# SF32LB58x register map
File version: 1.0
CPU: CM33 r0p1, little endian, MPU, FPU, 3 interrupt priority bits
Registers are 32-bit, read-write, reset 0x0 unless marked. A register's access mark holds for its fields unless they carry their own. Offsets are from the block's base; [hi:lo] are bit positions.

## WDT1
Base 0x40014000
Same registers: WDT2 0x5000B000, IWDT 0x5004C000
0x00 WDT_CVR0 — WatchDog Counter Value 0
  [23:0] COUNT_VALUE_0 — Count Value for 1st TimeOut
0x04 WDT_CVR1 — WatchDog Counter Value 1
  [23:0] COUNT_VALUE_1 — Count Value for 2nd TimeOut
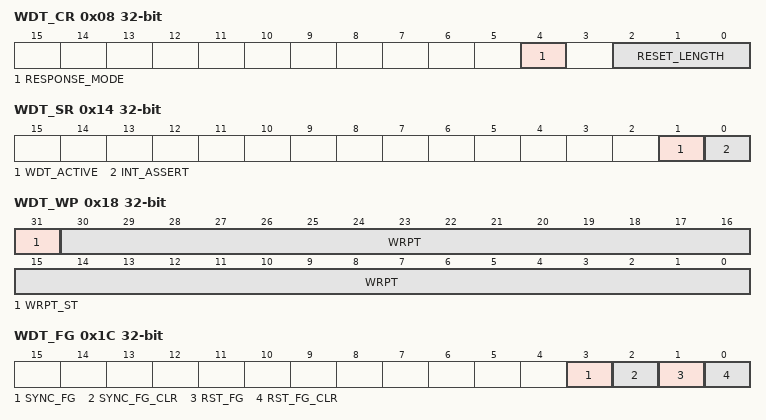
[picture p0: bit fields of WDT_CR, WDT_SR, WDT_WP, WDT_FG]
0x08 WDT_CR — WatchDog Control Register
  [4] RESPONSE_MODE — 0:reset only, 1:interrupt and reset
  [2:0] RESET_LENGTH — reset pulse length in number of wdt clock cycles
0x0C WDT_CCR — WatchDog Counter Control Register
  [7:0] COUNTER_CONTROL — SinglePulse /Write 8'h76 to restart, write8'h34 to stop, else do nothing
0x10 WDT_ICR — WatchDog Interrupt Clear Register
  [0] INT_CLR — SinglePulse /A pulse to clear interrupt
0x14 WDT_SR — WatchDog Status Register
  [1] WDT_ACTIVE — Watchdog runs when 1, else 0
  [0] INT_ASSERT — Interrupt assert when 1
0x18 WDT_WP — WatchDog Write Protect Register
  [31] WRPT_ST — 1 indicates write protect is active
  [30:0] WRPT — write 0x58ab99fc generate write_protect, write 0x51ff8621 to release
0x1C WDT_FG — WatchDog Flag Register
  [3] SYNC_FG — 1 indicates one transition from system clk to wdt clk has complicated
  [2] SYNC_FG_CLR — SinglePulse/A pulse to clear sync flag
  [1] RST_FG — 1 indicates wdt has already reset system
  [0] RST_FG_CLR — SinglePulse/A pulse to clear reset flag

## PDM1
Base 0x4001A000
Same registers: PDM2 0x4001B000
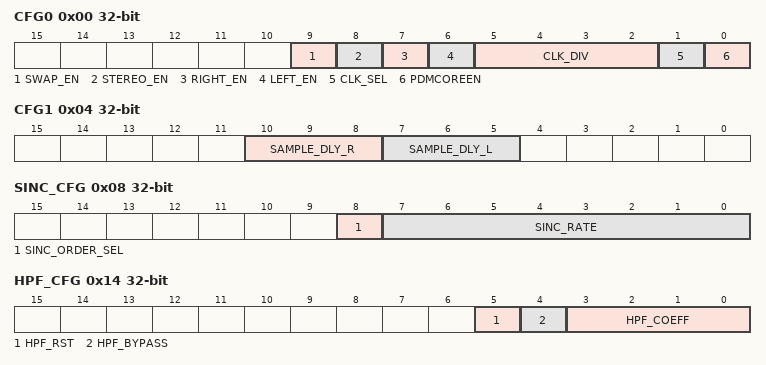
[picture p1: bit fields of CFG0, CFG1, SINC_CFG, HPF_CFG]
0x00 CFG0
  [9] SWAP_EN — 1: Swap right channel and left channel pdm data; 0: Not swap right channel and left channel pdm data
  [8] STEREO_EN — 1:Enable double channels pdm data sampling; 0: Disable double channels pdm data sampling
  [7] RIGHT_EN — 1: Enable right channel pdm data sampling; 0: Disable right channel pdm data sampling
  [6] LEFT_EN — 1: Enable left channel pdm data sampling; 0: Disable left channel pdm data sampling
  [5:2] CLK_DIV — Clock frequency division ratio of 3.072MHz or 9.6MHz according to register clk_sel
  [1] CLK_SEL — 1:Clk select dll 3.072MHz; 0: Clk selct xtal 9.6MHz
  [0] PDMCOREEN — 1:Enable pdm module; 0: Disable pdm module
0x04 CFG1
  [10:8] SAMPLE_DLY_R — The number of delay dff before the right data stream in processing
  [7:5] SAMPLE_DLY_L — The number of delay dff before the left data stream in processing
0x08 SINC_CFG
  [8] SINC_ORDER_SEL — 1:select four differentiators in sinc filter; 0:select three differentiators in sinc filter
  [7:0] SINC_RATE — dowmsampling rate of sinc filter
0x14 HPF_CFG
  [5] HPF_RST — 1:high-pass filter normal operation ; 0:reset high-pass filter
  [4] HPF_BYPASS — 1:bypass-high pass filter ; 0: enable high-pass filter
  [3:0] HPF_COEFF — coefficient of high-pass filter
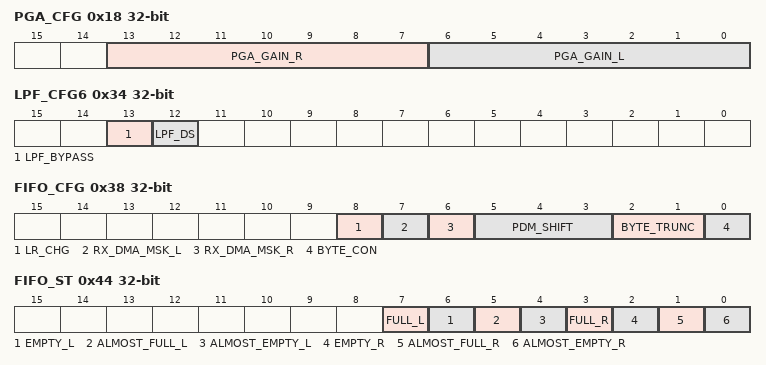
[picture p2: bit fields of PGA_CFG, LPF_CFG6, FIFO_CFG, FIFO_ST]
0x18 PGA_CFG
  [13:7] PGA_GAIN_R — right channel gain control , the range is -15dB~45dB. Resolution is 0.5dB/LSB
  [6:0] PGA_GAIN_L — left channel gain control , the range is -15dB~45dB. Resolution is 0.5dB/LSB
0x34 LPF_CFG6
  [13] LPF_BYPASS — 1:bypass low-pass filter ; 0: enable low-pass filter
  [12] LPF_DS — 1:downsampling rate of low pass filter is two;0:No downsampling of low pass filter
0x38 FIFO_CFG
  [8] LR_CHG — 1:exchange storage location of left and right channel; 0: don't exchange storage location of left and right channel
  [7] RX_DMA_MSK_L — 1:disable left channel dma request; 0: enable left channel dma request
  [6] RX_DMA_MSK_R — 1:disable right channel dma request; 0: enable right channel dma request
  [5:3] PDM_SHIFT — the number of data left shift for higher data accuracy
  [2:1] BYTE_TRUNC — 1: 16bits output ; 0: 24bits output ;2: 8bits output ; 3: 32bits output
  [0] BYTE_CON — 1: combine left channel and right channel; 0: not combine left channel and right channel
0x44 FIFO_ST
  [7] FULL_L — 1 indicates left channel fifo is full
  [6] EMPTY_L — 1 indicates left channel fifo is empty
  [5] ALMOST_FULL_L — 1 indicates left channel fifo is less than two full
  [4] ALMOST_EMPTY_L — 1 indicates left channel fifo is less than two datas left
  [3] FULL_R — 1 indicates right channel fifo is full
  [2] EMPTY_R — 1 indicates right channel fifo is empty
  [1] ALMOST_FULL_R — 1 indicates right channel fifo is less than two full
  [0] ALMOST_EMPTY_R — 1 indicates right channel fifo is less than two datas left
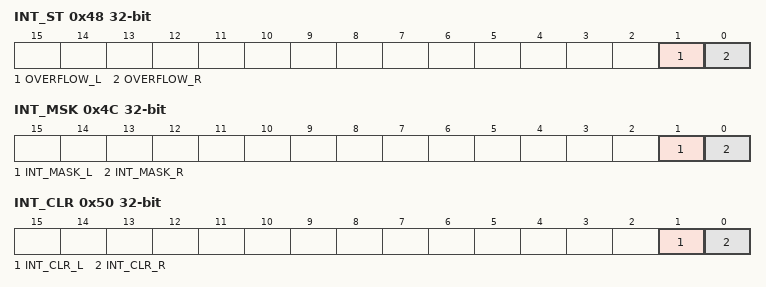
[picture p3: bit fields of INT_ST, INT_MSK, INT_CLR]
0x48 INT_ST
  [1] OVERFLOW_L — 1 indicates left channel fifo has already overflowed and as irq at same time
  [0] OVERFLOW_R — 1 indicates right channel fifo has already overflowed and as irq at same time
0x4C INT_MSK
  [1] INT_MASK_L — 1:disable left channel irq to system; 0: enable left channel irq to system
  [0] INT_MASK_R — 1:disable right channel irq to system; 0: enable right channel irq to system
0x50 INT_CLR
  [1] INT_CLR_L — clear left channel irq
  [0] INT_CLR_R — clear right channel irq
